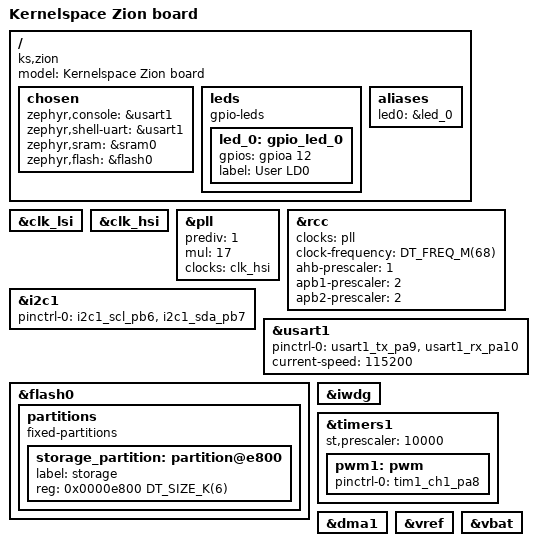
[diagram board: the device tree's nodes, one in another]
/*
 * Copyright (c) 2024 Kernelspace
 *
 * SPDX-License-Identifier: Apache-2.0
 */

/dts-v1/;
#include <st/f3/stm32f303X8.dtsi>
#include <st/f3/stm32f303k(6-8)tx-pinctrl.dtsi>
#include <zephyr/dt-bindings/input/input-event-codes.h>

/ {
	model = "Kernelspace Zion board";
	compatible = "ks,zion";

	chosen {
		zephyr,console = &usart1;
		zephyr,shell-uart = &usart1;
		zephyr,sram = &sram0;
		zephyr,flash = &flash0;
	};

	leds {
		compatible = "gpio-leds";

		led_0: gpio_led_0 {
			gpios = <&gpioa 12 GPIO_ACTIVE_HIGH>;
			label = "User LD0";
		};
	};

	aliases {
		led0 = &led_0;
	};
};

&clk_lsi {
	status = "okay";
};

&clk_hsi {
	status = "okay";
};

&pll {
	prediv = <1>; /* not used on 303k8 */
	mul = <17>;
	clocks = <&clk_hsi>;
	status = "okay";
};

&rcc {
	clocks = <&pll>;
	clock-frequency = <DT_FREQ_M(68)>;
	ahb-prescaler = <1>;
	apb1-prescaler = <2>;
	apb2-prescaler = <2>;
};

&i2c1 {
	pinctrl-0 = <&i2c1_scl_pb6 &i2c1_sda_pb7>;
	pinctrl-names = "default";
	status = "okay";
};

&usart1 {
	pinctrl-0 = <&usart1_tx_pa9 &usart1_rx_pa10>;
	pinctrl-names = "default";
	current-speed = <115200>;
	status = "okay";
};

&flash0 {
	partitions {
		compatible = "fixed-partitions";
		#address-cells = <1>;
		#size-cells = <1>;

		/* Set 6Kb of storage at the end of the 64Kb of flash */
		storage_partition: partition@e800 {
			label = "storage";
			reg = <0x0000e800 DT_SIZE_K(6)>;
		};
	};
};

&iwdg {
	status = "okay";
};

&timers1 {
	st,prescaler = <10000>;
	status = "okay";
	pwm1: pwm {
		status = "okay";
		pinctrl-0 = <&tim1_ch1_pa8>;
		pinctrl-names = "default";
	};
};

&dma1 {
	status = "okay";
};

&vref {
	status = "okay";
};

&vbat {
	status = "okay";
};
